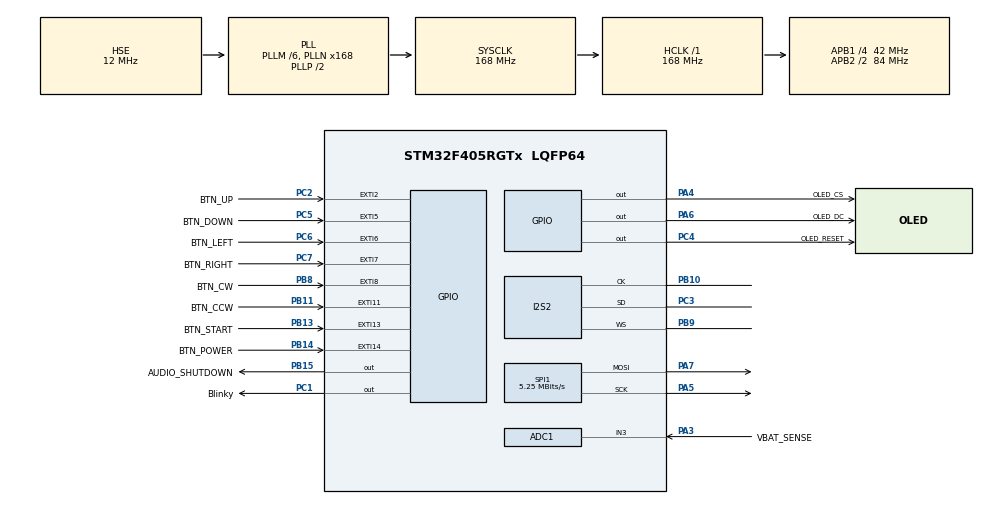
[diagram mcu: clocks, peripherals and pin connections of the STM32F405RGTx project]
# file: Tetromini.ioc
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ADC1.Channel-0\#ChannelRegularConversion=ADC_CHANNEL_3
ADC1.NbrOfConversionFlag=1
ADC1.Rank-0\#ChannelRegularConversion=1
ADC1.SamplingTime-0\#ChannelRegularConversion=ADC_SAMPLETIME_480CYCLES
ADC1.master=1
Dma.Request0=SPI1_TX
Dma.Request1=SPI2_TX
Dma.SPI1_TX.0.Direction=DMA_MEMORY_TO_PERIPH
Dma.SPI1_TX.0.FIFOMode=DMA_FIFOMODE_DISABLE
Dma.SPI1_TX.0.Instance=DMA2_Stream3
Dma.SPI1_TX.0.MemDataAlignment=DMA_MDATAALIGN_BYTE
Dma.SPI1_TX.0.MemInc=DMA_MINC_ENABLE
Dma.SPI1_TX.0.Mode=DMA_NORMAL
Dma.SPI1_TX.0.PeriphDataAlignment=DMA_PDATAALIGN_BYTE
Dma.SPI1_TX.0.PeriphInc=DMA_PINC_DISABLE
Dma.SPI1_TX.0.Priority=DMA_PRIORITY_LOW
Dma.SPI2_TX.1.Direction=DMA_MEMORY_TO_PERIPH
Dma.SPI2_TX.1.FIFOMode=DMA_FIFOMODE_DISABLE
Dma.SPI2_TX.1.Instance=DMA1_Stream4
Dma.SPI2_TX.1.MemDataAlignment=DMA_MDATAALIGN_HALFWORD
Dma.SPI2_TX.1.MemInc=DMA_MINC_ENABLE
Dma.SPI2_TX.1.Mode=DMA_CIRCULAR
Dma.SPI2_TX.1.PeriphDataAlignment=DMA_PDATAALIGN_HALFWORD
Dma.SPI2_TX.1.PeriphInc=DMA_PINC_DISABLE
Dma.SPI2_TX.1.Priority=DMA_PRIORITY_LOW
FREERTOS.Tasks01=defaultTask,24,128,StartDefaultTask,Default,NULL,Dynamic,NULL,NULL
I2S2.AudioFreq=I2S_AUDIOFREQ_48K
I2S2.ErrorAudioFreq=0.0 %
I2S2.FullDuplexMode=I2S_FULLDUPLEXMODE_DISABLE
I2S2.Instance=SPI$Index
I2S2.RealAudioFreq=48.0 KHz
I2S2.VirtualMode=I2S_MODE_MASTER
Mcu.Family=STM32F4
Mcu.Name=STM32F405RGTx
Mcu.Package=LQFP64
NVIC.DMA1_Stream4_IRQn=true\:5\:0\:false\:false\:true\:true\:false\:true\:true
NVIC.DMA2_Stream3_IRQn=true\:6\:0\:true\:false\:true\:true\:false\:true\:true
NVIC.EXTI15_10_IRQn=true\:7\:0\:true\:false\:true\:true\:true\:true\:true
NVIC.EXTI2_IRQn=true\:7\:0\:true\:false\:true\:true\:true\:true\:true
NVIC.EXTI9_5_IRQn=true\:7\:0\:true\:false\:true\:true\:true\:true\:true
NVIC.PriorityGroup=NVIC_PRIORITYGROUP_4
NVIC.TIM6_DAC_IRQn=true\:15\:0\:false\:false\:true\:false\:false\:true\:true
NVIC.TimeBase=TIM6_DAC_IRQn
NVIC.TimeBaseIP=TIM6
PA13.Mode=Serial_Wire
PA13.Signal=SYS_JTMS-SWDIO
PA14.Mode=Serial_Wire
PA14.Signal=SYS_JTCK-SWCLK
PA3.GPIO_Label=VBAT_SENSE
PA3.Signal=ADCx_IN3
PA4.GPIO_Label=OLED_CS
PA4.PinState=GPIO_PIN_SET
PA4.Signal=GPIO_Output
PA5.Mode=TX_Only_Simplex_Unidirect_Master
PA5.Signal=SPI1_SCK
PA6.GPIO_Label=OLED_DC
PA6.PinState=GPIO_PIN_SET
PA6.Signal=GPIO_Output
PA7.Mode=TX_Only_Simplex_Unidirect_Master
PA7.Signal=SPI1_MOSI
PB10.Mode=Half_Duplex_Master
PB10.Signal=I2S2_CK
PB11.GPIO_Label=BTN_CCW
PB11.GPIO_ModeDefaultEXTI=GPIO_MODE_IT_RISING_FALLING
PB11.GPIO_PuPd=GPIO_PULLUP
PB11.Signal=GPXTI11
PB13.GPIO_Label=BTN_START
PB13.GPIO_ModeDefaultEXTI=GPIO_MODE_IT_RISING_FALLING
PB13.GPIO_PuPd=GPIO_PULLUP
PB13.Signal=GPXTI13
PB14.GPIO_Label=BTN_POWER
PB14.GPIO_ModeDefaultEXTI=GPIO_MODE_IT_RISING_FALLING
PB14.GPIO_PuPd=GPIO_PULLUP
PB14.Signal=GPXTI14
PB15.GPIO_Label=AUDIO_SHUTDOWN
PB15.Signal=GPIO_Output
PB8.GPIO_Label=BTN_CW
PB8.GPIO_ModeDefaultEXTI=GPIO_MODE_IT_RISING_FALLING
PB8.GPIO_PuPd=GPIO_PULLUP
PB8.Signal=GPXTI8
PB9.Mode=Half_Duplex_Master
PB9.Signal=I2S2_WS
PC1.GPIO_Label=Blinky
PC1.Signal=GPIO_Output
PC2.GPIO_Label=BTN_UP
PC2.GPIO_ModeDefaultEXTI=GPIO_MODE_IT_RISING_FALLING
PC2.GPIO_PuPd=GPIO_PULLUP
PC2.Signal=GPXTI2
PC3.Mode=Half_Duplex_Master
PC3.Signal=I2S2_SD
PC4.GPIO_Label=OLED_RESET
PC4.Signal=GPIO_Output
PC5.GPIO_Label=BTN_DOWN
PC5.GPIO_ModeDefaultEXTI=GPIO_MODE_IT_RISING_FALLING
PC5.GPIO_PuPd=GPIO_PULLUP
PC5.Signal=GPXTI5
PC6.GPIO_Label=BTN_LEFT
PC6.GPIO_ModeDefaultEXTI=GPIO_MODE_IT_RISING_FALLING
PC6.GPIO_PuPd=GPIO_PULLUP
PC6.Signal=GPXTI6
PC7.GPIO_Label=BTN_RIGHT
PC7.GPIO_ModeDefaultEXTI=GPIO_MODE_IT_RISING_FALLING
PC7.GPIO_PuPd=GPIO_PULLUP
PC7.Signal=GPXTI7
PH0-OSC_IN.Mode=HSE-External-Oscillator
PH0-OSC_IN.Signal=RCC_OSC_IN
PH1-OSC_OUT.Mode=HSE-External-Oscillator
PH1-OSC_OUT.Signal=RCC_OSC_OUT
ProjectManager.HeapSize=0x200
ProjectManager.StackSize=0x400
ProjectManager.TargetToolchain=CMake
RCC.48MHZClocksFreq_Value=84000000
RCC.AHBFreq_Value=168000000
RCC.APB1CLKDivider=RCC_HCLK_DIV4
RCC.APB1Freq_Value=42000000
RCC.APB1TimFreq_Value=84000000
RCC.APB2CLKDivider=RCC_HCLK_DIV2
RCC.APB2Freq_Value=84000000
RCC.APB2TimFreq_Value=168000000
RCC.CortexFreq_Value=168000000
RCC.HCLKFreq_Value=168000000
RCC.HSE_VALUE=12000000
RCC.HSI_VALUE=16000000
RCC.LSE_VALUE=32768
RCC.PLLI2SN=96
RCC.PLLI2SR=5
RCC.PLLM=6
RCC.PLLN=168
RCC.PLLSourceVirtual=RCC_PLLSOURCE_HSE
RCC.SYSCLKFreq_VALUE=168000000
RCC.SYSCLKSource=RCC_SYSCLKSOURCE_PLLCLK
RCC.VCOOutputFreq_Value=336000000
SH.ADCx_IN3.0=ADC1_IN3,IN3
SPI1.BaudRatePrescaler=SPI_BAUDRATEPRESCALER_16
SPI1.CalculateBaudRate=5.25 MBits/s
SPI1.Direction=SPI_DIRECTION_2LINES
SPI1.Mode=SPI_MODE_MASTER
SPI1.VirtualType=VM_MASTER
VP_FREERTOS_VS_CMSIS_V2.Mode=CMSIS_V2
VP_SYS_VS_tim6.Mode=TIM6
board=custom

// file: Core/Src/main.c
/* USER CODE BEGIN Header */
/**
  ******************************************************************************
  * @file           : main.c
  * @brief          : Main program body
  ******************************************************************************
  * @attention
  *
  * Copyright (c) 2026 STMicroelectronics.
  * All rights reserved.
  *
  * This software is licensed under terms that can be found in the LICENSE file
  * in the root directory of this software component.
  * If no LICENSE file comes with this software, it is provided AS-IS.
  *
  ******************************************************************************
  */
/* USER CODE END Header */
#include "main.h"
#include "cmsis_os.h"
#include "adc.h"
#include "dma.h"
#include "i2s.h"
#include "spi.h"
#include "gpio.h"

void SystemClock_Config(void);
void MX_FREERTOS_Init(void);

int main(void)
{

  /* MCU Configuration--------------------------------------------------------*/

  /* Reset of all peripherals, Initializes the Flash interface and the Systick. */
  HAL_Init();

  /* Configure the system clock */
  SystemClock_Config();

  /* Initialize all configured peripherals */
  MX_GPIO_Init();
  MX_DMA_Init();
  MX_I2S2_Init();
  MX_SPI1_Init();
  MX_ADC1_Init();

  /* Init scheduler */
  osKernelInitialize();  /* Call init function for freertos objects (in cmsis_os2.c) */
  MX_FREERTOS_Init();

  /* Start scheduler */
  osKernelStart();

  /* We should never get here as control is now taken by the scheduler */

  /* Infinite loop */
  while (1)
  {

  }
}

void SystemClock_Config(void)
{
  RCC_OscInitTypeDef RCC_OscInitStruct = {0};
  RCC_ClkInitTypeDef RCC_ClkInitStruct = {0};

  /** Configure the main internal regulator output voltage
  */
  __HAL_RCC_PWR_CLK_ENABLE();
  __HAL_PWR_VOLTAGESCALING_CONFIG(PWR_REGULATOR_VOLTAGE_SCALE1);

  /** Initializes the RCC Oscillators according to the specified parameters
  * in the RCC_OscInitTypeDef structure.
  */
  RCC_OscInitStruct.OscillatorType = RCC_OSCILLATORTYPE_HSE;
  RCC_OscInitStruct.HSEState = RCC_HSE_ON;
  RCC_OscInitStruct.PLL.PLLState = RCC_PLL_ON;
  RCC_OscInitStruct.PLL.PLLSource = RCC_PLLSOURCE_HSE;
  RCC_OscInitStruct.PLL.PLLM = 6;
  RCC_OscInitStruct.PLL.PLLN = 168;
  RCC_OscInitStruct.PLL.PLLP = RCC_PLLP_DIV2;
  RCC_OscInitStruct.PLL.PLLQ = 4;
  if (HAL_RCC_OscConfig(&RCC_OscInitStruct) != HAL_OK)
  {
    Error_Handler();
  }

  /** Initializes the CPU, AHB and APB buses clocks
  */
  RCC_ClkInitStruct.ClockType = RCC_CLOCKTYPE_HCLK|RCC_CLOCKTYPE_SYSCLK
                              |RCC_CLOCKTYPE_PCLK1|RCC_CLOCKTYPE_PCLK2;
  RCC_ClkInitStruct.SYSCLKSource = RCC_SYSCLKSOURCE_PLLCLK;
  RCC_ClkInitStruct.AHBCLKDivider = RCC_SYSCLK_DIV1;
  RCC_ClkInitStruct.APB1CLKDivider = RCC_HCLK_DIV4;
  RCC_ClkInitStruct.APB2CLKDivider = RCC_HCLK_DIV2;

  if (HAL_RCC_ClockConfig(&RCC_ClkInitStruct, FLASH_LATENCY_5) != HAL_OK)
  {
    Error_Handler();
  }
}

void HAL_TIM_PeriodElapsedCallback(TIM_HandleTypeDef *htim)
{
  if (htim->Instance == TIM6)
  {
    HAL_IncTick();
  }
}

void Error_Handler(void)
{
  __disable_irq();
  while (1)
  {
  }
}

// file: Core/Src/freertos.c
/* USER CODE BEGIN Header */
/**
  ******************************************************************************
  * File Name          : freertos.c
  * Description        : Code for freertos applications
  ******************************************************************************
  * @attention
  *
  * Copyright (c) 2026 STMicroelectronics.
  * All rights reserved.
  *
  * This software is licensed under terms that can be found in the LICENSE file
  * in the root directory of this software component.
  * If no LICENSE file comes with this software, it is provided AS-IS.
  *
  ******************************************************************************
  */
/* USER CODE END Header */

#include "FreeRTOS.h"
#include "task.h"
#include "main.h"
#include "cmsis_os.h"

/* USER CODE BEGIN Includes */
#include "app.h"
/* USER CODE END Includes */

/* Definitions for defaultTask */
osThreadId_t defaultTaskHandle;
const osThreadAttr_t defaultTask_attributes = {
  .name = "defaultTask",
  .stack_size = 128 * 4,
  .priority = (osPriority_t) osPriorityNormal,
};

void StartDefaultTask(void *argument);

void MX_FREERTOS_Init(void); /* (MISRA C 2004 rule 8.1) */

void MX_FREERTOS_Init(void) {

  /* Create the thread(s) */
  /* creation of defaultTask */
  defaultTaskHandle = osThreadNew(StartDefaultTask, NULL, &defaultTask_attributes);

  /* USER CODE BEGIN RTOS_THREADS */
  /* add threads, ... */

  // Initializes all the threads linked to app_init() behaviour
  app_init();

  /* USER CODE END RTOS_THREADS */

}

void StartDefaultTask(void *argument)
{
  for(;;)
  {
    osDelay(1);
  }
}
